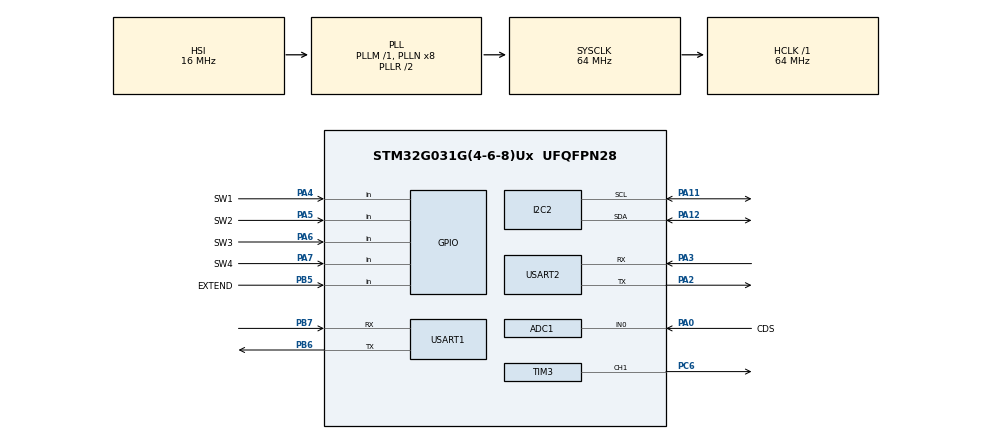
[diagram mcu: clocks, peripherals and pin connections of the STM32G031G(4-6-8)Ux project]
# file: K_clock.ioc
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ADC1.Channel-0\#ChannelRegularConversion=ADC_CHANNEL_0
ADC1.NbrOfConversionFlag=1
ADC1.Rank-0\#ChannelRegularConversion=1
ADC1.SamplingTime-0\#ChannelRegularConversion=ADC_SAMPLINGTIME_COMMON_1
ADC1.SelectedChannel=ADC_CHANNEL_0
ADC1.master=1
Dma.Request0=TIM3_CH1
Dma.TIM3_CH1.0.Direction=DMA_MEMORY_TO_PERIPH
Dma.TIM3_CH1.0.EventEnable=DISABLE
Dma.TIM3_CH1.0.Instance=DMA1_Channel1
Dma.TIM3_CH1.0.MemDataAlignment=DMA_MDATAALIGN_WORD
Dma.TIM3_CH1.0.MemInc=DMA_MINC_ENABLE
Dma.TIM3_CH1.0.Mode=DMA_NORMAL
Dma.TIM3_CH1.0.PeriphDataAlignment=DMA_PDATAALIGN_WORD
Dma.TIM3_CH1.0.PeriphInc=DMA_PINC_DISABLE
Dma.TIM3_CH1.0.Polarity=HAL_DMAMUX_REQ_GEN_RISING
Dma.TIM3_CH1.0.Priority=DMA_PRIORITY_VERY_HIGH
Dma.TIM3_CH1.0.RequestNumber=1
Dma.TIM3_CH1.0.SignalID=NONE
Dma.TIM3_CH1.0.SyncEnable=DISABLE
Dma.TIM3_CH1.0.SyncPolarity=HAL_DMAMUX_SYNC_NO_EVENT
Dma.TIM3_CH1.0.SyncRequestNumber=1
Dma.TIM3_CH1.0.SyncSignalID=NONE
I2C2.Timing=0x10707DBC
Mcu.Family=STM32G0
Mcu.Name=STM32G031G(4-6-8)Ux
Mcu.Package=UFQFPN28
NVIC.ADC1_IRQn=true\:0\:0\:false\:false\:true\:true\:true\:true
NVIC.DMA1_Channel1_IRQn=true\:0\:0\:false\:false\:true\:false\:true\:true
NVIC.I2C2_IRQn=true\:0\:0\:false\:false\:true\:true\:true\:true
NVIC.TIM3_IRQn=true\:0\:0\:false\:false\:true\:true\:true\:true
NVIC.USART1_IRQn=true\:0\:0\:false\:false\:true\:true\:true\:true
NVIC.USART2_IRQn=true\:0\:0\:false\:false\:true\:true\:true\:true
PA0.GPIO_Label=CDS
PA0.Mode=IN0
PA0.Signal=ADC1_IN0
PA11\ [PA9].Mode=I2C
PA11\ [PA9].Signal=I2C2_SCL
PA12\ [PA10].Mode=I2C
PA12\ [PA10].Signal=I2C2_SDA
PA13.Mode=Serial_Wire
PA13.Signal=SYS_SWDIO
PA14-BOOT0.Mode=Serial_Wire
PA14-BOOT0.Signal=SYS_SWCLK
PA2.Mode=Asynchronous
PA2.Signal=USART2_TX
PA3.Mode=Asynchronous
PA3.Signal=USART2_RX
PA4.GPIO_Label=SW1
PA4.Signal=GPIO_Input
PA5.GPIO_Label=SW2
PA5.Signal=GPIO_Input
PA6.GPIO_Label=SW3
PA6.Signal=GPIO_Input
PA7.GPIO_Label=SW4
PA7.Signal=GPIO_Input
PB5.GPIO_Label=EXTEND
PB5.Signal=GPIO_Input
PB6.Mode=Asynchronous
PB6.Signal=USART1_TX
PB7.Mode=Asynchronous
PB7.Signal=USART1_RX
PC14-OSC32_IN\ (PC14).Mode=LSE-External-Oscillator
PC14-OSC32_IN\ (PC14).Signal=RCC_OSC32_IN
PC15-OSC32_OUT\ (PC15).Mode=LSE-External-Oscillator
PC15-OSC32_OUT\ (PC15).Signal=RCC_OSC32_OUT
PC6.Signal=S_TIM3_CH1
ProjectManager.HeapSize=0x200
ProjectManager.StackSize=0x400
ProjectManager.TargetToolchain=EWARM V8.50
RCC.ADCFreq_Value=64000000
RCC.AHBFreq_Value=64000000
RCC.CortexFreq_Value=64000000
RCC.EXTERNAL_CLOCK_VALUE=12288000
RCC.HCLKFreq_Value=64000000
RCC.HSE_VALUE=8000000
RCC.HSI_VALUE=16000000
RCC.RTCClockSelection=RCC_RTCCLKSOURCE_LSE
RCC.SYSCLKFreq_VALUE=64000000
RCC.SYSCLKSource=RCC_SYSCLKSOURCE_PLLCLK
RCC.VCOOutputFreq_Value=128000000
RTC.Date=28
RTC.Hours=11
RTC.Minutes=30
RTC.Month=RTC_MONTH_MARCH
RTC.Year=24
SH.S_TIM3_CH1.0=TIM3_CH1,PWM Generation1 CH1
TIM3.Channel-PWM\ Generation1\ CH1=TIM_CHANNEL_1
USART1.VirtualMode-Asynchronous=VM_ASYNC
USART2.VirtualMode-Asynchronous=VM_ASYNC
VP_RTC_VS_RTC_Activate.Mode=RTC_Enabled
VP_RTC_VS_RTC_Calendar.Mode=RTC_Calendar
board=custom

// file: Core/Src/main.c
/* USER CODE BEGIN Header */
/**
  ******************************************************************************
  * @file           : main.c
  * @brief          : Main program body
  ******************************************************************************
  * @attention
  *
  * Copyright (c) 2024 STMicroelectronics.
  * All rights reserved.
  *
  * This software is licensed under terms that can be found in the LICENSE file
  * in the root directory of this software component.
  * If no LICENSE file comes with this software, it is provided AS-IS.
  *
  ******************************************************************************
  */
/* USER CODE END Header */
#include "main.h"

/* USER CODE BEGIN Includes */

#include "../../Main/Inc/usermain.h"
/* USER CODE END Includes */

/* USER CODE BEGIN PM */
#if 1
extern ADC_HandleTypeDef hadc1;

extern I2C_HandleTypeDef hi2c2;

extern RTC_HandleTypeDef hrtc;

extern TIM_HandleTypeDef htim3;
extern DMA_HandleTypeDef hdma_tim3_ch1;

extern UART_HandleTypeDef huart1;
extern UART_HandleTypeDef huart2;
#else
/* USER CODE END PM */

ADC_HandleTypeDef hadc1;

I2C_HandleTypeDef hi2c2;

RTC_HandleTypeDef hrtc;

extern TIM_HandleTypeDef htim3;
DMA_HandleTypeDef hdma_tim3_ch1;

extern UART_HandleTypeDef huart1;
extern UART_HandleTypeDef huart2;

/* USER CODE BEGIN PV */
#endif
/* USER CODE END PV */

void SystemClock_Config(void);
static void MX_GPIO_Init(void);
static void MX_DMA_Init(void);
static void MX_ADC1_Init(void);
static void MX_I2C2_Init(void);
static void MX_RTC_Init(void);
static void MX_USART1_UART_Init(void);
static void MX_USART2_UART_Init(void);
static void MX_TIM3_Init(void);

int main(void)
{

  /* MCU Configuration--------------------------------------------------------*/

  /* Reset of all peripherals, Initializes the Flash interface and the Systick. */
  HAL_Init();

  /* Configure the system clock */
  SystemClock_Config();

  /* Initialize all configured peripherals */
  MX_GPIO_Init();
  MX_DMA_Init();
  MX_ADC1_Init();
  MX_I2C2_Init();
  MX_RTC_Init();
  MX_USART1_UART_Init();
  MX_USART2_UART_Init();
  MX_TIM3_Init();
  /* USER CODE BEGIN 2 */
  user_init();
  /* USER CODE END 2 */

  /* Infinite loop */
  /* USER CODE BEGIN WHILE */
  while (1)
  {
    user_main();
    /* USER CODE END WHILE */

  }
}

void SystemClock_Config(void)
{
  RCC_OscInitTypeDef RCC_OscInitStruct = {0};
  RCC_ClkInitTypeDef RCC_ClkInitStruct = {0};

  /** Configure the main internal regulator output voltage
  */
  HAL_PWREx_ControlVoltageScaling(PWR_REGULATOR_VOLTAGE_SCALE1);

  /** Configure LSE Drive Capability
  */
  HAL_PWR_EnableBkUpAccess();
  __HAL_RCC_LSEDRIVE_CONFIG(RCC_LSEDRIVE_LOW);

  /** Initializes the RCC Oscillators according to the specified parameters
  * in the RCC_OscInitTypeDef structure.
  */
  RCC_OscInitStruct.OscillatorType = RCC_OSCILLATORTYPE_HSI|RCC_OSCILLATORTYPE_LSE;
  RCC_OscInitStruct.LSEState = RCC_LSE_ON;
  RCC_OscInitStruct.HSIState = RCC_HSI_ON;
  RCC_OscInitStruct.HSIDiv = RCC_HSI_DIV1;
  RCC_OscInitStruct.HSICalibrationValue = RCC_HSICALIBRATION_DEFAULT;
  RCC_OscInitStruct.PLL.PLLState = RCC_PLL_ON;
  RCC_OscInitStruct.PLL.PLLSource = RCC_PLLSOURCE_HSI;
  RCC_OscInitStruct.PLL.PLLM = RCC_PLLM_DIV1;
  RCC_OscInitStruct.PLL.PLLN = 8;
  RCC_OscInitStruct.PLL.PLLP = RCC_PLLP_DIV2;
  RCC_OscInitStruct.PLL.PLLQ = RCC_PLLQ_DIV2;
  RCC_OscInitStruct.PLL.PLLR = RCC_PLLR_DIV2;
  if (HAL_RCC_OscConfig(&RCC_OscInitStruct) != HAL_OK)
  {
    Error_Handler();
  }

  /** Initializes the CPU, AHB and APB buses clocks
  */
  RCC_ClkInitStruct.ClockType = RCC_CLOCKTYPE_HCLK|RCC_CLOCKTYPE_SYSCLK
                              |RCC_CLOCKTYPE_PCLK1;
  RCC_ClkInitStruct.SYSCLKSource = RCC_SYSCLKSOURCE_PLLCLK;
  RCC_ClkInitStruct.AHBCLKDivider = RCC_SYSCLK_DIV1;
  RCC_ClkInitStruct.APB1CLKDivider = RCC_HCLK_DIV1;

  if (HAL_RCC_ClockConfig(&RCC_ClkInitStruct, FLASH_LATENCY_2) != HAL_OK)
  {
    Error_Handler();
  }
}

static void MX_ADC1_Init(void)
{

  ADC_ChannelConfTypeDef sConfig = {0};

  /** Configure the global features of the ADC (Clock, Resolution, Data Alignment and number of conversion)
  */
  hadc1.Instance = ADC1;
  hadc1.Init.ClockPrescaler = ADC_CLOCK_SYNC_PCLK_DIV2;
  hadc1.Init.Resolution = ADC_RESOLUTION_12B;
  hadc1.Init.DataAlign = ADC_DATAALIGN_RIGHT;
  hadc1.Init.ScanConvMode = ADC_SCAN_DISABLE;
  hadc1.Init.EOCSelection = ADC_EOC_SINGLE_CONV;
  hadc1.Init.LowPowerAutoWait = DISABLE;
  hadc1.Init.LowPowerAutoPowerOff = DISABLE;
  hadc1.Init.ContinuousConvMode = DISABLE;
  hadc1.Init.NbrOfConversion = 1;
  hadc1.Init.DiscontinuousConvMode = DISABLE;
  hadc1.Init.ExternalTrigConv = ADC_SOFTWARE_START;
  hadc1.Init.ExternalTrigConvEdge = ADC_EXTERNALTRIGCONVEDGE_NONE;
  hadc1.Init.DMAContinuousRequests = DISABLE;
  hadc1.Init.Overrun = ADC_OVR_DATA_PRESERVED;
  hadc1.Init.SamplingTimeCommon1 = ADC_SAMPLETIME_1CYCLE_5;
  hadc1.Init.SamplingTimeCommon2 = ADC_SAMPLETIME_1CYCLE_5;
  hadc1.Init.OversamplingMode = DISABLE;
  hadc1.Init.TriggerFrequencyMode = ADC_TRIGGER_FREQ_HIGH;
  if (HAL_ADC_Init(&hadc1) != HAL_OK)
  {
    Error_Handler();
  }

  /** Configure Regular Channel
  */
  sConfig.Channel = ADC_CHANNEL_0;
  sConfig.Rank = ADC_REGULAR_RANK_1;
  sConfig.SamplingTime = ADC_SAMPLINGTIME_COMMON_1;
  if (HAL_ADC_ConfigChannel(&hadc1, &sConfig) != HAL_OK)
  {
    Error_Handler();
  }

}

static void MX_I2C2_Init(void)
{

  hi2c2.Instance = I2C2;
  hi2c2.Init.Timing = 0x10707DBC;
  hi2c2.Init.OwnAddress1 = 0;
  hi2c2.Init.AddressingMode = I2C_ADDRESSINGMODE_7BIT;
  hi2c2.Init.DualAddressMode = I2C_DUALADDRESS_DISABLE;
  hi2c2.Init.OwnAddress2 = 0;
  hi2c2.Init.OwnAddress2Masks = I2C_OA2_NOMASK;
  hi2c2.Init.GeneralCallMode = I2C_GENERALCALL_DISABLE;
  hi2c2.Init.NoStretchMode = I2C_NOSTRETCH_DISABLE;
  if (HAL_I2C_Init(&hi2c2) != HAL_OK)
  {
    Error_Handler();
  }

  /** Configure Analogue filter
  */
  if (HAL_I2CEx_ConfigAnalogFilter(&hi2c2, I2C_ANALOGFILTER_ENABLE) != HAL_OK)
  {
    Error_Handler();
  }

  /** Configure Digital filter
  */
  if (HAL_I2CEx_ConfigDigitalFilter(&hi2c2, 0) != HAL_OK)
  {
    Error_Handler();
  }

}

static void MX_RTC_Init(void)
{

  RTC_TimeTypeDef sTime = {0};
  RTC_DateTypeDef sDate = {0};

  /** Initialize RTC Only
  */
  hrtc.Instance = RTC;
  hrtc.Init.HourFormat = RTC_HOURFORMAT_24;
  hrtc.Init.AsynchPrediv = 127;
  hrtc.Init.SynchPrediv = 255;
  hrtc.Init.OutPut = RTC_OUTPUT_DISABLE;
  hrtc.Init.OutPutRemap = RTC_OUTPUT_REMAP_NONE;
  hrtc.Init.OutPutPolarity = RTC_OUTPUT_POLARITY_HIGH;
  hrtc.Init.OutPutType = RTC_OUTPUT_TYPE_OPENDRAIN;
  hrtc.Init.OutPutPullUp = RTC_OUTPUT_PULLUP_NONE;
  if (HAL_RTC_Init(&hrtc) != HAL_OK)
  {
    Error_Handler();
  }

  /** Initialize RTC and set the Time and Date
  */
  sTime.Hours = 0x11;
  sTime.Minutes = 0x30;
  sTime.Seconds = 0x0;
  sTime.SubSeconds = 0x0;
  sTime.DayLightSaving = RTC_DAYLIGHTSAVING_NONE;
  sTime.StoreOperation = RTC_STOREOPERATION_RESET;
  if (HAL_RTC_SetTime(&hrtc, &sTime, RTC_FORMAT_BCD) != HAL_OK)
  {
    Error_Handler();
  }
  sDate.WeekDay = RTC_WEEKDAY_MONDAY;
  sDate.Month = RTC_MONTH_MARCH;
  sDate.Date = 0x28;
  sDate.Year = 0x24;

  if (HAL_RTC_SetDate(&hrtc, &sDate, RTC_FORMAT_BCD) != HAL_OK)
  {
    Error_Handler();
  }

}

static void MX_TIM3_Init(void)
{

  TIM_MasterConfigTypeDef sMasterConfig = {0};
  TIM_OC_InitTypeDef sConfigOC = {0};

  htim3.Instance = TIM3;
  htim3.Init.Prescaler = 0;
  htim3.Init.CounterMode = TIM_COUNTERMODE_UP;
  htim3.Init.Period = 65535;
  htim3.Init.ClockDivision = TIM_CLOCKDIVISION_DIV1;
  htim3.Init.AutoReloadPreload = TIM_AUTORELOAD_PRELOAD_DISABLE;
  if (HAL_TIM_PWM_Init(&htim3) != HAL_OK)
  {
    Error_Handler();
  }
  sMasterConfig.MasterOutputTrigger = TIM_TRGO_RESET;
  sMasterConfig.MasterSlaveMode = TIM_MASTERSLAVEMODE_DISABLE;
  if (HAL_TIMEx_MasterConfigSynchronization(&htim3, &sMasterConfig) != HAL_OK)
  {
    Error_Handler();
  }
  sConfigOC.OCMode = TIM_OCMODE_PWM1;
  sConfigOC.Pulse = 0;
  sConfigOC.OCPolarity = TIM_OCPOLARITY_HIGH;
  sConfigOC.OCFastMode = TIM_OCFAST_DISABLE;
  if (HAL_TIM_PWM_ConfigChannel(&htim3, &sConfigOC, TIM_CHANNEL_1) != HAL_OK)
  {
    Error_Handler();
  }
  HAL_TIM_MspPostInit(&htim3);

}

static void MX_USART1_UART_Init(void)
{

  huart1.Instance = USART1;
  huart1.Init.BaudRate = 115200;
  huart1.Init.WordLength = UART_WORDLENGTH_8B;
  huart1.Init.StopBits = UART_STOPBITS_1;
  huart1.Init.Parity = UART_PARITY_NONE;
  huart1.Init.Mode = UART_MODE_TX_RX;
  huart1.Init.HwFlowCtl = UART_HWCONTROL_NONE;
  huart1.Init.OverSampling = UART_OVERSAMPLING_16;
  huart1.Init.OneBitSampling = UART_ONE_BIT_SAMPLE_DISABLE;
  huart1.Init.ClockPrescaler = UART_PRESCALER_DIV1;
  huart1.AdvancedInit.AdvFeatureInit = UART_ADVFEATURE_NO_INIT;
  if (HAL_UART_Init(&huart1) != HAL_OK)
  {
    Error_Handler();
  }
  if (HAL_UARTEx_SetTxFifoThreshold(&huart1, UART_TXFIFO_THRESHOLD_1_8) != HAL_OK)
  {
    Error_Handler();
  }
  if (HAL_UARTEx_SetRxFifoThreshold(&huart1, UART_RXFIFO_THRESHOLD_1_8) != HAL_OK)
  {
    Error_Handler();
  }
  if (HAL_UARTEx_DisableFifoMode(&huart1) != HAL_OK)
  {
    Error_Handler();
  }

}

static void MX_USART2_UART_Init(void)
{

  huart2.Instance = USART2;
  huart2.Init.BaudRate = 115200;
  huart2.Init.WordLength = UART_WORDLENGTH_8B;
  huart2.Init.StopBits = UART_STOPBITS_1;
  huart2.Init.Parity = UART_PARITY_NONE;
  huart2.Init.Mode = UART_MODE_TX_RX;
  huart2.Init.HwFlowCtl = UART_HWCONTROL_NONE;
  huart2.Init.OverSampling = UART_OVERSAMPLING_16;
  huart2.Init.OneBitSampling = UART_ONE_BIT_SAMPLE_DISABLE;
  huart2.Init.ClockPrescaler = UART_PRESCALER_DIV1;
  huart2.AdvancedInit.AdvFeatureInit = UART_ADVFEATURE_NO_INIT;
  if (HAL_UART_Init(&huart2) != HAL_OK)
  {
    Error_Handler();
  }

}

static void MX_DMA_Init(void)
{

  /* DMA controller clock enable */
  __HAL_RCC_DMA1_CLK_ENABLE();

  /* DMA interrupt init */
  /* DMA1_Channel1_IRQn interrupt configuration */
  HAL_NVIC_SetPriority(DMA1_Channel1_IRQn, 0, 0);
  HAL_NVIC_EnableIRQ(DMA1_Channel1_IRQn);

}

static void MX_GPIO_Init(void)
{
  GPIO_InitTypeDef GPIO_InitStruct = {0};

  /* GPIO Ports Clock Enable */
  __HAL_RCC_GPIOC_CLK_ENABLE();
  __HAL_RCC_GPIOA_CLK_ENABLE();
  __HAL_RCC_GPIOB_CLK_ENABLE();

  /*Configure GPIO pins : SW1_Pin SW2_Pin SW3_Pin SW4_Pin */
  GPIO_InitStruct.Pin = SW1_Pin|SW2_Pin|SW3_Pin|SW4_Pin;
  GPIO_InitStruct.Mode = GPIO_MODE_INPUT;
  GPIO_InitStruct.Pull = GPIO_NOPULL;
  HAL_GPIO_Init(GPIOA, &GPIO_InitStruct);

  /*Configure GPIO pin : EXTEND_Pin */
  GPIO_InitStruct.Pin = EXTEND_Pin;
  GPIO_InitStruct.Mode = GPIO_MODE_INPUT;
  GPIO_InitStruct.Pull = GPIO_NOPULL;
  HAL_GPIO_Init(EXTEND_GPIO_Port, &GPIO_InitStruct);

}

void Error_Handler(void)
{
  __disable_irq();
  while (1)
  {
  }
}
